AUTOSAR XML (schema 00046)
package /ComponentTypes
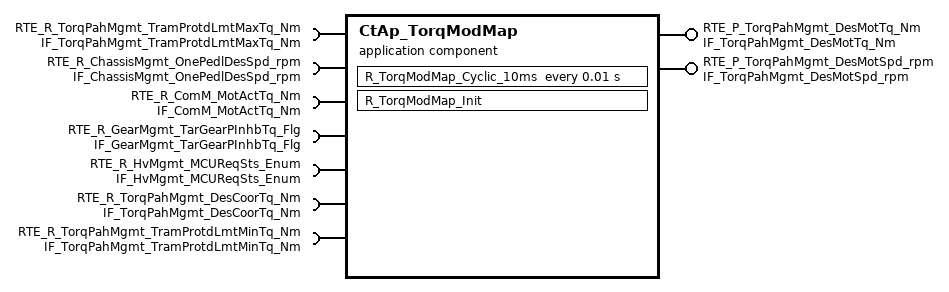
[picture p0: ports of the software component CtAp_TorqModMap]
  application sw component type CtAp_TorqModMap
    provide port RTE_P_TorqPahMgmt_DesMotTq_Nm: nonqueued-sender-com-spec{data-element=tec_TorqPahMgmt_DesMotTq_Nm, init-value=0}, provided-interface=IF_TorqPahMgmt_DesMotTq_Nm
    require port RTE_R_TorqPahMgmt_TramProtdLmtMaxTq_Nm: nonqueued-receiver-com-spec{data-element=tec_TorqPahMgmt_TramProtdLmtMaxTq_Nm, filter=data-filter-type=ALWAYS, init-value=0}, required-interface=IF_TorqPahMgmt_TramProtdLmtMaxTq_Nm
    provide port RTE_P_TorqPahMgmt_DesMotSpd_rpm: nonqueued-sender-com-spec{data-element=tec_TorqPahMgmt_DesMotSpd_rpm, init-value=0}, provided-interface=IF_TorqPahMgmt_DesMotSpd_rpm
    6 x require port:
      RTE_R_ChassisMgmt_OnePedlDesSpd_rpm: nonqueued-receiver-com-spec{data-element=tec_ChassisMgmt_OnePedlDesSpd_rpm, filter=data-filter-type=ALWAYS, init-value=0}, required-interface=IF_ChassisMgmt_OnePedlDesSpd_rpm
      RTE_R_ComM_MotActTq_Nm: nonqueued-receiver-com-spec{data-element=tec_ComM_MotActTq_Nm, filter=data-filter-type=ALWAYS, init-value=0}, required-interface=IF_ComM_MotActTq_Nm
      RTE_R_GearMgmt_TarGearPInhbTq_Flg: nonqueued-receiver-com-spec{data-element=tec_GearMgmt_TarGearPInhbTq_Flg, filter=data-filter-type=ALWAYS, init-value=0}, required-interface=IF_GearMgmt_TarGearPInhbTq_Flg
      RTE_R_HvMgmt_MCUReqSts_Enum: nonqueued-receiver-com-spec{data-element=tec_HvMgmt_MCUReqSts_Enum, filter=data-filter-type=ALWAYS, init-value=0}, required-interface=IF_HvMgmt_MCUReqSts_Enum
      RTE_R_TorqPahMgmt_DesCoorTq_Nm: nonqueued-receiver-com-spec{data-element=tec_TorqPahMgmt_DesCoorTq_Nm, filter=data-filter-type=ALWAYS, init-value=0}, required-interface=IF_TorqPahMgmt_DesCoorTq_Nm
      RTE_R_TorqPahMgmt_TramProtdLmtMinTq_Nm: nonqueued-receiver-com-spec{data-element=tec_TorqPahMgmt_TramProtdLmtMinTq_Nm, filter=data-filter-type=ALWAYS, init-value=0}, required-interface=IF_TorqPahMgmt_TramProtdLmtMinTq_Nm
    behavior CtAp_TorqModMap_InternalBehavior
      init event CtAp_TorqModMap_InitEvent: start-on-event=R_TorqModMap_Init
      timing event TMT_R_TorqModMap_Cyclic_10ms: start-on-event=R_TorqModMap_Cyclic_10ms, period=0.01
      runnable R_TorqModMap_Init
      runnable R_TorqModMap_Cyclic_10ms
        data-receive-point-by-arguments:
          7 x access:
            REC_RTE_R_ChassisMgmt_OnePedlDesSpd_rpm_tec_ChassisMgmt_OnePedlDesSpd_rpm: accessed-variable=RTE_R_ChassisMgmt_OnePedlDesSpd_rpm.tec_ChassisMgmt_OnePedlDesSpd_rpm
            REC_RTE_R_ComM_MotActTq_Nm_tec_ComM_MotActTq_Nm: accessed-variable=RTE_R_ComM_MotActTq_Nm.tec_ComM_MotActTq_Nm
            REC_RTE_R_GearMgmt_TarGearPInhbTq_Flg_tec_GearMgmt_TarGearPInhbTq_Flg: accessed-variable=RTE_R_GearMgmt_TarGearPInhbTq_Flg.tec_GearMgmt_TarGearPInhbTq_Flg
            REC_RTE_R_HvMgmt_MCUReqSts_Enum_tec_HvMgmt_MCUReqSts_Enum: accessed-variable=RTE_R_HvMgmt_MCUReqSts_Enum.tec_HvMgmt_MCUReqSts_Enum
            REC_RTE_R_TorqPahMgmt_DesCoorTq_Nm_tec_TorqPahMgmt_DesCoorTq_Nm: accessed-variable=RTE_R_TorqPahMgmt_DesCoorTq_Nm.tec_TorqPahMgmt_DesCoorTq_Nm
            REC_RTE_R_TorqPahMgmt_TramProtdLmtMaxTq_Nm_tec_TorqPahMgmt_TramProtdLmtMaxTq_Nm: accessed-variable=RTE_R_TorqPahMgmt_TramProtdLmtMaxTq_Nm.tec_TorqPahMgmt_TramProtdLmtMaxTq_Nm
            REC_RTE_R_TorqPahMgmt_TramProtdLmtMinTq_Nm_tec_TorqPahMgmt_TramProtdLmtMinTq_Nm: accessed-variable=RTE_R_TorqPahMgmt_TramProtdLmtMinTq_Nm.tec_TorqPahMgmt_TramProtdLmtMinTq_Nm
        data-send-points:
          access SEND_RTE_P_TorqPahMgmt_DesMotSpd_rpm_tec_TorqPahMgmt_DesMotSpd_rpm: accessed-variable=RTE_P_TorqPahMgmt_DesMotSpd_rpm.tec_TorqPahMgmt_DesMotSpd_rpm
          access SEND_RTE_P_TorqPahMgmt_DesMotTq_Nm_tec_TorqPahMgmt_DesMotTq_Nm: accessed-variable=RTE_P_TorqPahMgmt_DesMotTq_Nm.tec_TorqPahMgmt_DesMotTq_Nm
  swc implementation CtAp_TorqModMap_Implementation: behavior=CtAp_TorqModMap_InternalBehavior
    code-descriptors:
      code Default: artifact-descriptors=autosar-engineering-object=category=SWOBJ
